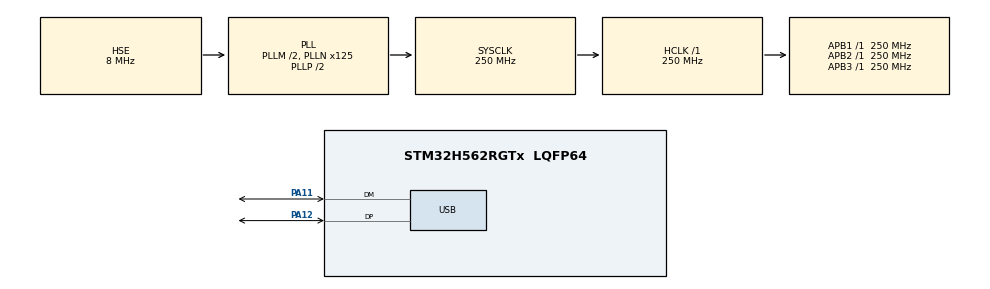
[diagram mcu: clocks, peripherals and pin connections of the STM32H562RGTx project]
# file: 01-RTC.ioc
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ADC2.Channel-0\#ChannelRegularConversion=ADC_CHANNEL_VBAT
ADC2.ClockPrescaler=ADC_CLOCK_ASYNC_DIV4
ADC2.ContinuousConvMode=ENABLE
ADC2.DMAContinuousRequests=ENABLE
ADC2.MonitoredBy-0\#ChannelRegularConversion=__NULL
ADC2.NbrOfConversionFlag=1
ADC2.OffsetNumber-0\#ChannelRegularConversion=ADC_OFFSET_NONE
ADC2.Rank-0\#ChannelRegularConversion=1
ADC2.SamplingTime-0\#ChannelRegularConversion=ADC_SAMPLETIME_247CYCLES_5
BOOTPATH.BootPathName=LEGACY
BOOTPATH.UserSelectedBootPath=LEGACY
CORTEX_M33_NS.userName=CORTEX_M33
GPDMA1.CIRCULARMODE_GPDMACH0=ENABLE
GPDMA1.DESTDATAWIDTH_GPDMACH0=DMA_DEST_DATAWIDTH_HALFWORD
GPDMA1.IPHANDLE_GPDMACH0-SIMPLEREQUEST_GPDMACH0=__NULL
GPDMA1.PRIORITY_LL_CIRCULAR_GPDMACH0=DMA_LOW_PRIORITY_MID_WEIGHT
GPDMA1.REQUEST_GPDMACH0=GPDMA1_REQUEST_ADC2
GPDMA1.SRCDATAWIDTH_GPDMACH0=DMA_SRC_DATAWIDTH_HALFWORD
Mcu.Family=STM32H5
Mcu.Name=STM32H562RGTx
Mcu.Package=LQFP64
NVIC.GPDMA1_Channel0_IRQn=true\:1\:0\:true\:false\:true\:false\:true\:true
NVIC.PriorityGroup=NVIC_PRIORITYGROUP_4
NVIC.USB_DRD_FS_IRQn=true\:0\:0\:false\:false\:true\:true\:true\:true
PA11.Mode=Device
PA11.Signal=USB_DM
PA12.Mode=Device
PA12.Signal=USB_DP
PA13(JTMS/SWDIO).Mode=Serial_Wire
PA13(JTMS/SWDIO).Signal=DEBUG_JTMS-SWDIO
PA14(JTCK/SWCLK).Mode=Serial_Wire
PA14(JTCK/SWCLK).Signal=DEBUG_JTCK-SWCLK
PC14-OSC32_IN(OSC32_IN).Mode=LSE-External-Oscillator
PC14-OSC32_IN(OSC32_IN).Signal=RCC_OSC32_IN
PC15-OSC32_OUT(OSC32_OUT).Mode=LSE-External-Oscillator
PC15-OSC32_OUT(OSC32_OUT).Signal=RCC_OSC32_OUT
PH0-OSC_IN(PH0).Mode=HSE-External-Oscillator
PH0-OSC_IN(PH0).Signal=RCC_OSC_IN
PH1-OSC_OUT(PH1).Mode=HSE-External-Oscillator
PH1-OSC_OUT(PH1).Signal=RCC_OSC_OUT
ProjectManager.HeapSize=0x200
ProjectManager.StackSize=0x2000
ProjectManager.TargetToolchain=MDK-ARM V5.32
RCC.ADCCLockSelection=RCC_ADCDACCLKSOURCE_PLL2R
RCC.ADCFreq_Value=125000000
RCC.AHBFreq_Value=250000000
RCC.APB1Freq_Value=250000000
RCC.APB1TimFreq_Value=250000000
RCC.APB2Freq_Value=250000000
RCC.APB2TimFreq_Value=250000000
RCC.APB3Freq_Value=250000000
RCC.CSI_VALUE=4000000
RCC.CortexFreq_Value=250000000
RCC.EPOD_VALUE=8000000
RCC.HCLKFreq_Value=250000000
RCC.HSE_VALUE=8000000
RCC.HSI48_VALUE=48000000
RCC.HSI_VALUE=64000000
RCC.LSE_Drive_Capability=RCC_LSEDRIVE_MEDIUMLOW
RCC.LSIRC_VALUE=32000
RCC.PLL2M=2
RCC.PLL2N=125
RCC.PLL2R=4
RCC.PLL2Source=RCC_PLL2_SOURCE_HSE
RCC.PLLM=2
RCC.PLLN=125
RCC.PLLSourceVirtual=RCC_PLL1_SOURCE_HSE
RCC.RTCClockSelection=RCC_RTCCLKSOURCE_LSE
RCC.SYSCLKFreq_VALUE=250000000
RCC.SYSCLKSource=RCC_SYSCLKSOURCE_PLLCLK
RCC.USBFreq_Value=48000000
RCC.VCOOutputFreq_Value=500000000
RTC.Format=RTC_FORMAT_BIN
RTC.Month=RTC_MONTH_JULY
RTC.Year=24
USB.VirtualMode=Device_Only
USBX.BSP.number=1
USBX.Core_System=1
USBX.USBD_CDCACM_EPINCMD_ADDR=2
USBX.USBD_CDCACM_EPIN_ADDR=1
USBX.USBX_DEVICE_SYS_SIZE=6*1024
USBX.UX_DEVICE_CDC_ACM=1
USBX.UX_DEVICE_CLASS_CDC_ACM_WRITE_AUTO_ZLP=1
USBX.UX_Device_Controller=1
USBX.UX_Device_CoreStack=1
USBX.UX_SLAVE_REQUEST_DATA_MAX_LENGTH=512
USBX0.BSP.STBoard=false
USBX0.BSP.api=Unknown
USBX0.BSP.instance=USB
USBX0.BSP.ip=USB
USBX0.BSP.mode=Device_Only
USBX0.BSP.name=USB_Device
USBX0.BSP.solution=USB
VP_ADC2_Vbat_Input.Mode=IN-Vbat
VP_BOOTPATH_VS_BOOTPATH.Mode=BP_Activate
VP_CORTEX_M33_NS_VS_Hclk.Mode=Hclk_Mode
VP_GPDMA1_VS_GPDMACH0.Mode=SIMPLEREQUEST_GPDMACH0
VP_ICACHE_VS_ICACHE.Mode=DefaultMode
VP_MEMORYMAP_VS_MEMORYMAP.Mode=CurAppReg
VP_PWR_VS_DBSignals.Mode=DisableDeadBatterySignals
VP_PWR_VS_LPOM.Mode=PowerOptimisation
VP_PWR_VS_SECSignals.Mode=Security/Privilege
VP_RCC_USB.Mode=CRS SYNC Source USB
VP_RTC_VS_RTC_Activate.Mode=RTC_Enabled
VP_RTC_VS_RTC_Calendar.Mode=RTC_Calendar
VP_USBX_Core_System.Mode=Core_System
VP_USBX_UX\ Device\ CDC\ ACM\ Class_FS.Mode=UX_Device_class_CDC_ACM_FS
VP_USBX_UX\ Device\ Controller_FS.Mode=UX_Device_Controller_FS
VP_USBX_UX\ Device\ CoreStack_FS.Mode=UX_Device_CoreStack_FS
board=custom

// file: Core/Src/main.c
/* USER CODE BEGIN Header */
/**
  ******************************************************************************
  * @file           : main.c
  * @brief          : Main program body
  ******************************************************************************
  * @attention
  *
  * Copyright (c) 2024 STMicroelectronics.
  * All rights reserved.
  *
  * This software is licensed under terms that can be found in the LICENSE file
  * in the root directory of this software component.
  * If no LICENSE file comes with this software, it is provided AS-IS.
  *
  ******************************************************************************
  */
/* USER CODE END Header */
#include "main.h"
#include "adc.h"
#include "gpdma.h"
#include "icache.h"
#include "memorymap.h"
#include "rtc.h"
#include "usb.h"
#include "app_usbx_device.h"
#include "gpio.h"

/* USER CODE BEGIN Includes */
#include "board.h"
/* USER CODE END Includes */

void SystemClock_Config(void);

/* USER CODE BEGIN 0 */
uint16_t adc_inp;
/* USER CODE END 0 */

int main(void)
{

  /* MCU Configuration--------------------------------------------------------*/

  /* Reset of all peripherals, Initializes the Flash interface and the Systick. */
  HAL_Init();

  /* Configure the system clock */
  SystemClock_Config();

  /* Initialize all configured peripherals */
  MX_GPIO_Init();
  MX_GPDMA1_Init();
  MX_RTC_Init();
  MX_USBX_Device_Init();
  MX_ADC2_Init();
  MX_ICACHE_Init();
  /* USER CODE BEGIN 2 */
	MX_USB_PCD_Init();
	/* Set Rx and Tx FIFO */
	HAL_PCDEx_PMAConfig(&hpcd_USB_DRD_FS, 0x00, PCD_SNG_BUF, 0x14);
  HAL_PCDEx_PMAConfig(&hpcd_USB_DRD_FS, 0x80, PCD_SNG_BUF, 0x54);
  HAL_PCDEx_PMAConfig(&hpcd_USB_DRD_FS, 0x81, PCD_SNG_BUF, 0x94);
  HAL_PCDEx_PMAConfig(&hpcd_USB_DRD_FS, 0x01, PCD_SNG_BUF, 0xD4);
  HAL_PCDEx_PMAConfig(&hpcd_USB_DRD_FS, 0x82, PCD_SNG_BUF, 0x114);

  ux_dcd_stm32_initialize((ULONG)USB_DRD_FS, (ULONG)&hpcd_USB_DRD_FS);

	/* Start the USB device */
	HAL_PCD_Start(&hpcd_USB_DRD_FS);

	board_led_init();
	board_button_init();
  /* USER CODE END 2 */

  /* Infinite loop */
  /* USER CODE BEGIN WHILE */
	HAL_ADCEx_Calibration_Start(&hadc2,ADC_SINGLE_ENDED);
	HAL_ADC_Start_DMA(&hadc2,(uint32_t *)&adc_inp,1);

	uint32_t tick = HAL_GetTick();
	uint32_t tick_usb = tick;
	uint32_t tick_usb_tx = tick;
	uint32_t tick_button = tick;

	uint8_t txbuf[50];
	ULONG length;
	ULONG actual_length;
	length = sprintf(( char *)txbuf,"Hello! WeAct Studio\r\n");
	UINT write_state = UX_STATE_RESET;
	UINT ux_status = UX_STATE_RESET;
  while (1)
  {
		tick = HAL_GetTick();
		if(tick >= tick_usb)
		{
			tick_usb = tick + 1;
			ux_device_stack_tasks_run();
		}

		if(tick >= tick_button)
		{
			if(board_button_getstate())
			{
				tick_button = tick + 100;
				board_led_toggle();
				length = sprintf(( char *)txbuf,"Key Pressed\r\n");
			}
			else
			{
				tick_button = tick + 500;
				RTC_DateTypeDef sdatestructureget;
        RTC_TimeTypeDef stimestructureget;
        static uint8_t Seconds_o;
        int text_lenth;

        /* Get the RTC current Time */
        HAL_RTC_GetTime(&hrtc, &stimestructureget, RTC_FORMAT_BIN);
        /* Get the RTC current Date */
        HAL_RTC_GetDate(&hrtc, &sdatestructureget, RTC_FORMAT_BIN);

        if(Seconds_o != stimestructureget.Seconds)
        {
          Seconds_o = stimestructureget.Seconds;

          board_led_set(1);

          length = sprintf((char *) &txbuf,"20%02d.%02d.%02d %02d:%02d %02d ,%dmV\r\n",sdatestructureget.Year,sdatestructureget.Month,sdatestructureget.Date, \
                                            stimestructureget.Hours,stimestructureget.Minutes,stimestructureget.Seconds,(((uint32_t)adc_inp)*3300)>>10);
        }
        else
        {
          board_led_set(0);
        }
			}
		}

		if(tick >= tick_usb_tx)
		{
			tick_usb_tx = tick + 1;

			extern UX_SLAVE_CLASS_CDC_ACM  *cdc_acm;
			if(cdc_acm != UX_NULL)
			{
				switch(write_state)
				{
				case UX_STATE_RESET:

					ux_status = ux_device_class_cdc_acm_write_run(cdc_acm, txbuf,length, &actual_length);

					if (ux_status != UX_STATE_WAIT)
					{
						/* Reset state.  */
						write_state = UX_STATE_RESET;
						break;
					}
					write_state = UX_STATE_WAIT;
					break;

				case UX_STATE_WAIT:
					/* Continue to run state machine.  */
					ux_status = ux_device_class_cdc_acm_write_run(cdc_acm, UX_NULL, 0, &actual_length);
					/* Check if there is  fatal error.  */
					if (ux_status < UX_STATE_IDLE)
					{
						/* Reset state.  */
						write_state = UX_STATE_RESET;
						break;
					}
					/* Check if dataset is transmitted */
					if (ux_status <= UX_STATE_NEXT)
					{
						write_state = UX_STATE_RESET;
						tick_usb_tx = tick + 1000;
					}
					/* Keep waiting.  */
					break;
				default:
					break;
				}
			}
		}
    /* USER CODE END WHILE */

  }
}

void SystemClock_Config(void)
{
  RCC_OscInitTypeDef RCC_OscInitStruct = {0};
  RCC_ClkInitTypeDef RCC_ClkInitStruct = {0};
  RCC_CRSInitTypeDef RCC_CRSInitStruct = {0};

  /** Configure the main internal regulator output voltage
  */
  __HAL_PWR_VOLTAGESCALING_CONFIG(PWR_REGULATOR_VOLTAGE_SCALE0);

  while(!__HAL_PWR_GET_FLAG(PWR_FLAG_VOSRDY)) {}

  /** Configure LSE Drive Capability
  *  Warning : Only applied when the LSE is disabled.
  */
  HAL_PWR_EnableBkUpAccess();
  __HAL_RCC_LSEDRIVE_CONFIG(RCC_LSEDRIVE_MEDIUMLOW);

  /** Initializes the RCC Oscillators according to the specified parameters
  * in the RCC_OscInitTypeDef structure.
  */
  RCC_OscInitStruct.OscillatorType = RCC_OSCILLATORTYPE_HSI48|RCC_OSCILLATORTYPE_HSE
                              |RCC_OSCILLATORTYPE_LSE;
  RCC_OscInitStruct.HSEState = RCC_HSE_ON;
  RCC_OscInitStruct.LSEState = RCC_LSE_ON;
  RCC_OscInitStruct.HSI48State = RCC_HSI48_ON;
  RCC_OscInitStruct.PLL.PLLState = RCC_PLL_ON;
  RCC_OscInitStruct.PLL.PLLSource = RCC_PLL1_SOURCE_HSE;
  RCC_OscInitStruct.PLL.PLLM = 2;
  RCC_OscInitStruct.PLL.PLLN = 125;
  RCC_OscInitStruct.PLL.PLLP = 2;
  RCC_OscInitStruct.PLL.PLLQ = 2;
  RCC_OscInitStruct.PLL.PLLR = 2;
  RCC_OscInitStruct.PLL.PLLRGE = RCC_PLL1_VCIRANGE_2;
  RCC_OscInitStruct.PLL.PLLVCOSEL = RCC_PLL1_VCORANGE_WIDE;
  RCC_OscInitStruct.PLL.PLLFRACN = 0;
  if (HAL_RCC_OscConfig(&RCC_OscInitStruct) != HAL_OK)
  {
    Error_Handler();
  }

  /** Initializes the CPU, AHB and APB buses clocks
  */
  RCC_ClkInitStruct.ClockType = RCC_CLOCKTYPE_HCLK|RCC_CLOCKTYPE_SYSCLK
                              |RCC_CLOCKTYPE_PCLK1|RCC_CLOCKTYPE_PCLK2
                              |RCC_CLOCKTYPE_PCLK3;
  RCC_ClkInitStruct.SYSCLKSource = RCC_SYSCLKSOURCE_PLLCLK;
  RCC_ClkInitStruct.AHBCLKDivider = RCC_SYSCLK_DIV1;
  RCC_ClkInitStruct.APB1CLKDivider = RCC_HCLK_DIV1;
  RCC_ClkInitStruct.APB2CLKDivider = RCC_HCLK_DIV1;
  RCC_ClkInitStruct.APB3CLKDivider = RCC_HCLK_DIV1;

  if (HAL_RCC_ClockConfig(&RCC_ClkInitStruct, FLASH_LATENCY_5) != HAL_OK)
  {
    Error_Handler();
  }

  /** Enable the CRS APB clock
  */
  __HAL_RCC_CRS_CLK_ENABLE();

  /** Configures CRS
  */
  RCC_CRSInitStruct.Prescaler = RCC_CRS_SYNC_DIV1;
  RCC_CRSInitStruct.Source = RCC_CRS_SYNC_SOURCE_USB;
  RCC_CRSInitStruct.Polarity = RCC_CRS_SYNC_POLARITY_RISING;
  RCC_CRSInitStruct.ReloadValue = __HAL_RCC_CRS_RELOADVALUE_CALCULATE(48000000,1000);
  RCC_CRSInitStruct.ErrorLimitValue = 34;
  RCC_CRSInitStruct.HSI48CalibrationValue = 32;

  HAL_RCCEx_CRSConfig(&RCC_CRSInitStruct);
}

void Error_Handler(void)
{
  __disable_irq();
  while (1)
  {
  }
}
